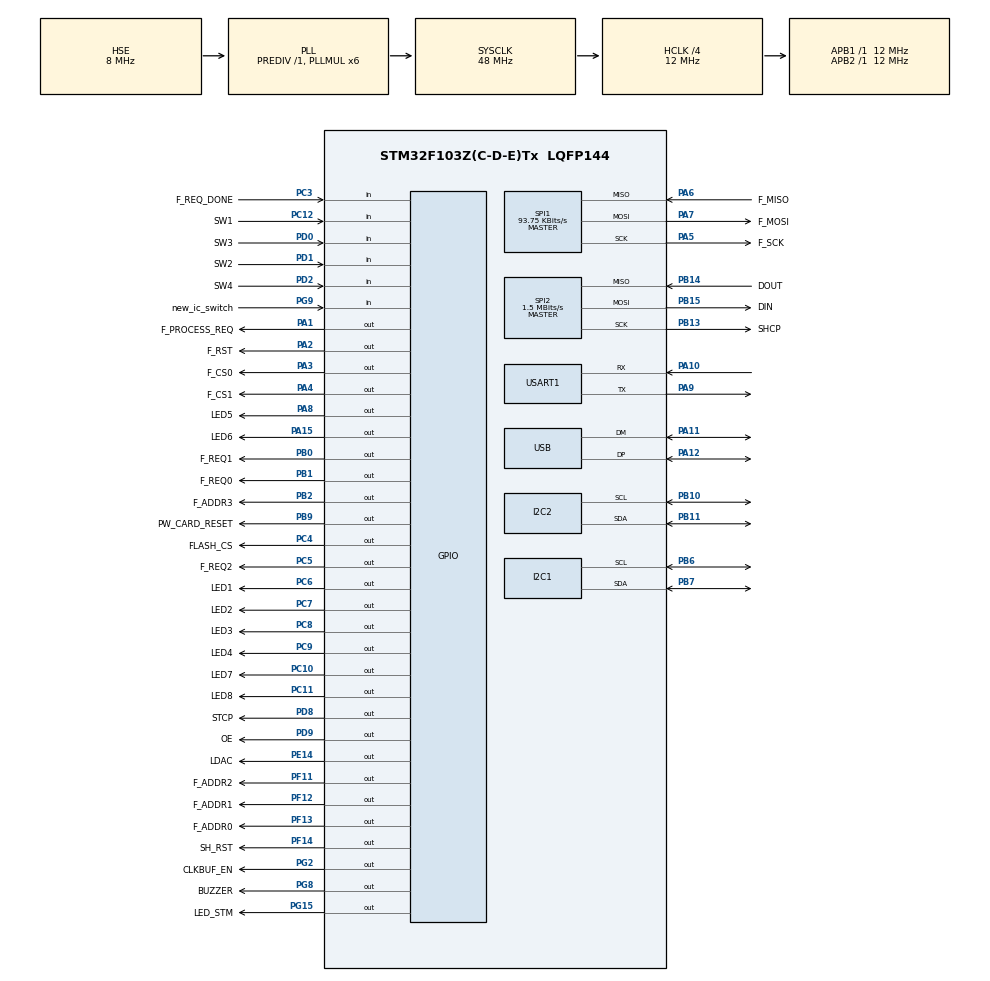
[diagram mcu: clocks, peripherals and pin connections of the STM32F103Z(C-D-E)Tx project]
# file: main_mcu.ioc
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Mcu.Family=STM32F1
Mcu.Name=STM32F103Z(C-D-E)Tx
Mcu.Package=LQFP144
NVIC.PriorityGroup=NVIC_PRIORITYGROUP_4
NVIC.USB_LP_CAN1_RX0_IRQn=true\:0\:0\:false\:false\:true\:false\:true
OSC_IN.Mode=HSE-External-Oscillator
OSC_IN.Signal=RCC_OSC_IN
OSC_OUT.Mode=HSE-External-Oscillator
OSC_OUT.Signal=RCC_OSC_OUT
PA1.GPIO_Label=F_PROCESS_REQ
PA1.Signal=GPIO_Output
PA10.Mode=Asynchronous
PA10.Signal=USART1_RX
PA11.Mode=Device
PA11.Signal=USB_DM
PA12.Mode=Device
PA12.Signal=USB_DP
PA13.Mode=Serial_Wire
PA13.Signal=SYS_JTMS-SWDIO
PA14.Mode=Serial_Wire
PA14.Signal=SYS_JTCK-SWCLK
PA15.GPIO_Label=LED6
PA15.Signal=GPIO_Output
PA2.GPIO_Label=F_RST
PA2.Signal=GPIO_Output
PA3.GPIO_Label=F_CS0
PA3.Signal=GPIO_Output
PA4.GPIO_Label=F_CS1
PA4.Signal=GPIO_Output
PA5.GPIO_Label=F_SCK
PA5.Mode=Full_Duplex_Master
PA5.Signal=SPI1_SCK
PA6.GPIO_Label=F_MISO
PA6.Mode=Full_Duplex_Master
PA6.Signal=SPI1_MISO
PA7.GPIO_Label=F_MOSI
PA7.Mode=Full_Duplex_Master
PA7.Signal=SPI1_MOSI
PA8.GPIO_Label=LED5
PA8.Signal=GPIO_Output
PA9.Mode=Asynchronous
PA9.Signal=USART1_TX
PB0.GPIO_Label=F_REQ1
PB0.Signal=GPIO_Output
PB1.GPIO_Label=F_REQ0
PB1.Signal=GPIO_Output
PB10.Mode=I2C
PB10.Signal=I2C2_SCL
PB11.Mode=I2C
PB11.Signal=I2C2_SDA
PB13.GPIO_Label=SHCP
PB13.Mode=Full_Duplex_Master
PB13.Signal=SPI2_SCK
PB14.GPIO_Label=DOUT
PB14.Mode=Full_Duplex_Master
PB14.Signal=SPI2_MISO
PB15.GPIO_Label=DIN
PB15.Mode=Full_Duplex_Master
PB15.Signal=SPI2_MOSI
PB2.GPIO_Label=F_ADDR3
PB2.Signal=GPIO_Output
PB6.Mode=I2C
PB6.Signal=I2C1_SCL
PB7.Mode=I2C
PB7.Signal=I2C1_SDA
PB9.GPIO_Label=PW_CARD_RESET
PB9.GPIO_ModeDefaultOutputPP=GPIO_MODE_OUTPUT_OD
PB9.Signal=GPIO_Output
PC10.GPIO_Label=LED7
PC10.Signal=GPIO_Output
PC11.GPIO_Label=LED8
PC11.Signal=GPIO_Output
PC12.GPIO_Label=SW1
PC12.Signal=GPIO_Input
PC3.GPIO_Label=F_REQ_DONE
PC3.Signal=GPIO_Input
PC4.GPIO_Label=FLASH_CS
PC4.Signal=GPIO_Output
PC5.GPIO_Label=F_REQ2
PC5.Signal=GPIO_Output
PC6.GPIO_Label=LED1
PC6.Signal=GPIO_Output
PC7.GPIO_Label=LED2
PC7.Signal=GPIO_Output
PC8.GPIO_Label=LED3
PC8.Signal=GPIO_Output
PC9.GPIO_Label=LED4
PC9.Signal=GPIO_Output
PD0.GPIO_Label=SW3
PD0.Signal=GPIO_Input
PD1.GPIO_Label=SW2
PD1.Signal=GPIO_Input
PD2.GPIO_Label=SW4
PD2.Signal=GPIO_Input
PD8.GPIO_Label=STCP
PD8.Signal=GPIO_Output
PD9.GPIO_Label=OE
PD9.Signal=GPIO_Output
PE14.GPIO_Label=LDAC
PE14.Signal=GPIO_Output
PF11.GPIO_Label=F_ADDR2
PF11.Signal=GPIO_Output
PF12.GPIO_Label=F_ADDR1
PF12.Signal=GPIO_Output
PF13.GPIO_Label=F_ADDR0
PF13.Signal=GPIO_Output
PF14.GPIO_Label=SH_RST
PF14.Signal=GPIO_Output
PG15.GPIO_Label=LED_STM
PG15.GPIO_PuPd=GPIO_PULLUP
PG15.Signal=GPIO_Output
PG2.GPIO_Label=CLKBUF_EN
PG2.Signal=GPIO_Output
PG8.GPIO_Label=BUZZER
PG8.Signal=GPIO_Output
PG9.GPIO_Label=new_ic_switch
PG9.GPIO_PuPd=GPIO_PULLUP
PG9.Signal=GPIO_Input
ProjectManager.HeapSize=0x200
ProjectManager.StackSize=0x400
ProjectManager.TargetToolchain=STM32CubeIDE
RCC.AHBCLKDivider=RCC_SYSCLK_DIV4
RCC.AHBFreq_Value=12000000
RCC.APB1Freq_Value=12000000
RCC.APB1TimFreq_Value=12000000
RCC.APB2Freq_Value=12000000
RCC.APB2TimFreq_Value=12000000
RCC.HCLKFreq_Value=12000000
RCC.PLLMUL=RCC_PLL_MUL6
RCC.SYSCLKFreq_VALUE=48000000
RCC.SYSCLKSource=RCC_SYSCLKSOURCE_PLLCLK
RCC.USBFreq_Value=48000000
SPI1.BaudRatePrescaler=SPI_BAUDRATEPRESCALER_128
SPI1.CalculateBaudRate=93.75 KBits/s
SPI1.Direction=SPI_DIRECTION_2LINES
SPI1.Mode=SPI_MODE_MASTER
SPI1.VirtualType=VM_MASTER
SPI2.BaudRatePrescaler=SPI_BAUDRATEPRESCALER_8
SPI2.CalculateBaudRate=1.5 MBits/s
SPI2.Direction=SPI_DIRECTION_2LINES
SPI2.FirstBit=SPI_FIRSTBIT_LSB
SPI2.Mode=SPI_MODE_MASTER
SPI2.VirtualType=VM_MASTER
USART1.VirtualMode=VM_ASYNC
USB_DEVICE.APP_RX_DATA_SIZE=1000
USB_DEVICE.APP_TX_DATA_SIZE=1000
USB_DEVICE.CLASS_NAME_FS=CDC
USB_DEVICE.VirtualMode=Cdc
USB_DEVICE.VirtualModeFS=Cdc_FS
VP_USB_DEVICE_VS_USB_DEVICE_CDC_FS.Mode=CDC_FS
board=custom

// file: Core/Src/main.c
/* USER CODE BEGIN Header */
/**
  ******************************************************************************
  * @file           : main.c
  * @brief          : Main program body
  ******************************************************************************
  * @attention
  *
  * <h2><center>&copy; Copyright (c) 2020 STMicroelectronics.
  * All rights reserved.</center></h2>
  *
  * This software component is licensed by ST under BSD 3-Clause license,
  * the "License"; You may not use this file except in compliance with the
  * License. You may obtain a copy of the License at:
  *                        opensource.org/licenses/BSD-3-Clause
  *
  ******************************************************************************
  */
/* USER CODE END Header */
#include "main.h"
#include "i2c.h"
#include "spi.h"
#include "usart.h"
#include "usb_device.h"
#include "gpio.h"

/* USER CODE BEGIN Includes */
#include "defines.h"
#include "global_space.h"
#include "setup_and_loop.h"
#include "fpga.h"
#include "si5351.h"
/* USER CODE END Includes */

void SystemClock_Config(void);
/* USER CODE BEGIN PFP */
#include "function_prototype.h"

/* USER CODE END PFP */

int main(void)
{

  /* MCU Configuration--------------------------------------------------------*/

  /* Reset of all peripherals, Initializes the Flash interface and the Systick. */
  HAL_Init();

  /* Configure the system clock */
  SystemClock_Config();

  /* Initialize all configured peripherals */
  MX_GPIO_Init();
  MX_USB_DEVICE_Init();
  MX_SPI1_Init();
  MX_I2C1_Init();
  MX_I2C2_Init();
  MX_USART1_UART_Init();
  MX_SPI2_Init();
  /* USER CODE BEGIN 2 */

	setup();
  /* USER CODE END 2 */

  /* Infinite loop */
  /* USER CODE BEGIN WHILE */
  while (1)
  {
//	  HAL_GPIO_TogglePin(LED_STM_GPIO_Port, LED_STM_Pin);
//	  HAL_Delay(500);

    /* USER CODE END WHILE */

    /* USER CODE BEGIN 3 */
	  main_loop();

  }
  /* USER CODE END 3 */
}

void SystemClock_Config(void)
{
  RCC_OscInitTypeDef RCC_OscInitStruct = {0};
  RCC_ClkInitTypeDef RCC_ClkInitStruct = {0};
  RCC_PeriphCLKInitTypeDef PeriphClkInit = {0};

  /** Initializes the RCC Oscillators according to the specified parameters
  * in the RCC_OscInitTypeDef structure.
  */
  RCC_OscInitStruct.OscillatorType = RCC_OSCILLATORTYPE_HSE;
  RCC_OscInitStruct.HSEState = RCC_HSE_ON;
  RCC_OscInitStruct.HSEPredivValue = RCC_HSE_PREDIV_DIV1;
  RCC_OscInitStruct.HSIState = RCC_HSI_ON;
  RCC_OscInitStruct.PLL.PLLState = RCC_PLL_ON;
  RCC_OscInitStruct.PLL.PLLSource = RCC_PLLSOURCE_HSE;
  RCC_OscInitStruct.PLL.PLLMUL = RCC_PLL_MUL6;
  if (HAL_RCC_OscConfig(&RCC_OscInitStruct) != HAL_OK)
  {
    Error_Handler();
  }
  /** Initializes the CPU, AHB and APB buses clocks
  */
  RCC_ClkInitStruct.ClockType = RCC_CLOCKTYPE_HCLK|RCC_CLOCKTYPE_SYSCLK
                              |RCC_CLOCKTYPE_PCLK1|RCC_CLOCKTYPE_PCLK2;
  RCC_ClkInitStruct.SYSCLKSource = RCC_SYSCLKSOURCE_PLLCLK;
  RCC_ClkInitStruct.AHBCLKDivider = RCC_SYSCLK_DIV4;
  RCC_ClkInitStruct.APB1CLKDivider = RCC_HCLK_DIV1;
  RCC_ClkInitStruct.APB2CLKDivider = RCC_HCLK_DIV1;

  if (HAL_RCC_ClockConfig(&RCC_ClkInitStruct, FLASH_LATENCY_1) != HAL_OK)
  {
    Error_Handler();
  }
  PeriphClkInit.PeriphClockSelection = RCC_PERIPHCLK_USB;
  PeriphClkInit.UsbClockSelection = RCC_USBCLKSOURCE_PLL;
  if (HAL_RCCEx_PeriphCLKConfig(&PeriphClkInit) != HAL_OK)
  {
    Error_Handler();
  }
}

void Error_Handler(void)
{
}

/************************ (C) COPYRIGHT STMicroelectronics *****END OF FILE****/
